# A31T41x register map
Vendor: ABOV Semiconductor Co., Ltd.; File version: 1.0
CPU: CM0PLUS r0p1, little endian, no MPU, no FPU, VTOR, vendor SysTick, 2 interrupt priority bits
Registers are 32-bit, read-write, reset 0x0 unless marked. A register's access mark holds for its fields unless they carry their own. Offsets are from the block's base; [hi:lo] are bit positions; {n}, {i} and the like mark numbered series; 'fields as' and 'values as' point back to an identical list.

## FRT — Free Run Timer
Base 0x40000600
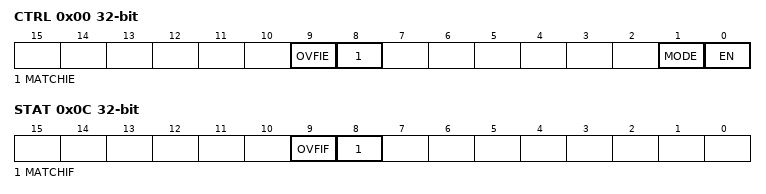
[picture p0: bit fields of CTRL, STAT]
0x00 CTRL — FRT control register
  [9] OVFIE — Whether to enable or disable the FRT counter overflow interrupt in Free-run timer mode (MODE = 0)
    0=Disable (Interrupt Disable); 1=Enable (Interrupt Enable)
  [8] MATCHIE — Whether to enable or disable the FRT counter match interrupt in Periodic timer mode (MODE = 1)
    0=Disable (Interrupt Disable); 1=Enable (Interrupt Enable)
  [1] MODE — FRT mode selection
    0=Free-Run_Timer; 1=Periodic_Timer
  [0] EN — Whether to enable or disable the FRT
    0=Disable (FRT Disable); 1=Enable (FRT Enable)
0x04 MCNT reset 0xFFFFFFFF — FRT match counter register
  [31:0] MCNT — FRTs match counter value
0x08 CNT — FRT counter register
  [31:0] CNT — FRT count data
0x0C STAT — FRT status register
  [9] OVFIF — FRT counter overflow interrupt flag
  [8] MATCHIF — FRT counter match interrupt flag

## I2C — Inter-Integrated Circuit
Base 0x5000A000
Same registers: I2C0 0x4000A000, I2C1 0x4000A100, I2C2 0x4000A200
0x00 DR reset 0xFF — I2C data register
  [7:0] ICDR — In transmit mode, the data stored in this register is outputted from pin SDA in the serial data line. In receive mode, data received at pin SDA is stored in this register; hence, the stored data is loaded by reading this register
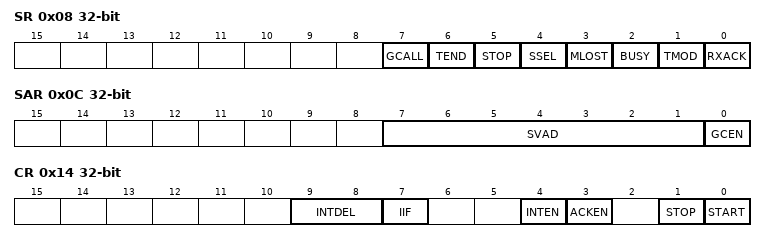
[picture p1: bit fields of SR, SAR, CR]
0x08 SR — I2C status register
  [7] GCALL — This bit signifies different things, depending on whether the I2C is in master or slave mode.
  [6] TEND — One-byte transmit end flag
  [5] STOP — Stop flag
  [4] SSEL — Slave flag
  [3] MLOST — Mastership loss flag
  [2] BUSY ro — Bus busy flag
  [1] TMOD ro — Transmit / receive mode flag
  [0] RXACK — Rx ACK flag
0x0C SAR — I2C slave address register
  [7:1] SVAD — 7-bit slave address
  [0] GCEN — Whether to enable or disable general call
0x14 CR — I2C Control Register
  [9:8] INTDEL — Internal delay between address and data transfers (Or between two data transfers)
    0=1_ICnSCLL (Delay = 1*ICnSCLL); 1=2_ICnSCLL (Delay = 2*ICnSCLL); 2=4_ICnSCLL (Delay = 4*ICnSCLL); 3=8_ICnSCLL (Delay = 8*ICnSCLL)
  [7] IIF ro — Interrupt flag
  [4] INTEN — Whether to enable or disable interrupts
  [3] ACKEN — Whether to enable or disable ACK in receive mode
    0=No ACK signal is generated; 1=ACK (ACK signal is generated)
  [1] STOP — Whether to enable or disable stop
  [0] START — Transmission start in master mode
0x18 SCLL reset 0xFFFF — I2C SCL low duration register
  [15:0] SCLL — SCL low duration value
0x1C SCLH reset 0xFFFF — I2C SCL high duration register
  [15:0] SCLH — SCL high duration value
0x20 SDH reset 0x7FFF — I2C SDA hold register
  [14:0] SDH — SDA hold time value

## CMP — Comparator
Base 0x4000B380
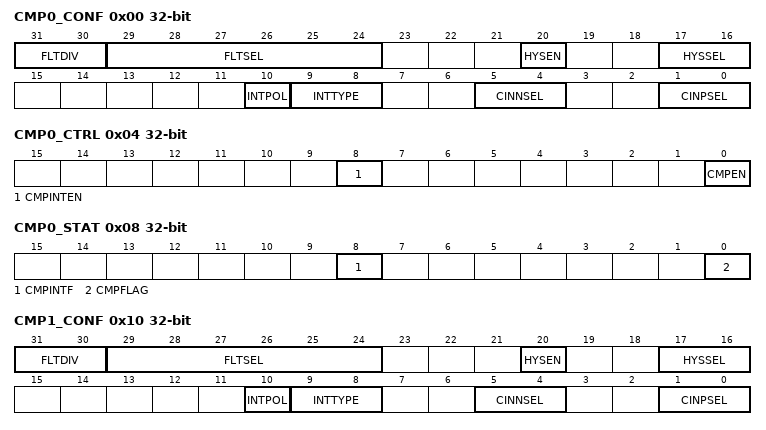
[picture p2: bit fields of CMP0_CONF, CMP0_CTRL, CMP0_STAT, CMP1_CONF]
0x00 CMP0_CONF — Comparator 0 Configure Register
  [31:30] FLTDIV — Digital filter clock divider
  [29:24] FLTSEL — Digital filter count
  [20] HYSEN — Hysteresis enable bit
  [17:16] HYSSEL — Hysteresis selection bit
    0=Hys_40mV (40mV Hysteresis); 1=Hys_80mV (80mV Hysteresis); 2=Hys_120mV (120mV Hysteresis); 3=Hys_160mV (160mV Hysteresis)
  [10] INTPOL — Interrupt polarity selection bit
    0=Low (Low (Falling)); 1=High (Rising)
  [9:8] INTTYPE — Interrupt type selection bit
    0=Disable; 1=Level; 2=Single_edge; 3=Both_edge
  [5:4] CINNSEL — Reference (input -) selection bit
    0=External Reference; 2=Ground; 3=Internal Reference
  [1:0] CINPSEL — Source (input +) selection bit
    0=CP0A; 1=CPB; 2=Ground; 3=Internal Reference
0x04 CMP0_CTRL — Comparator 0 Control Register
  [8] CMPINTEN — Comparator interrupt enable bit
  [0] CMPEN — Comparator enable bit
0x08 CMP0_STAT — Comparator 0 Status Register
  [8] CMPINTF — Comparator interrupt flag bit
    0=Not_occurred (Interrupt not occurred); 1=occurred (Interrupt occurred (writing '1' to the bit clears it to '0'))
  [0] CMPFLAG ro — Comparator output status
    0=Low; 1=High
0x10 CMP1_CONF — Comparator 1 Configure Register
  [31:30] FLTDIV — Digital filter clock divider
  [29:24] FLTSEL — Digital filter count
  [20] HYSEN — Hysteresis enable bit
  [17:16] HYSSEL — Hysteresis selection bit
    values as CMP0_CONF.HYSSEL
  [10] INTPOL — Interrupt polarity selection bit
    0=Low (Low (Falling)); 1=High (Rising)
  [9:8] INTTYPE — Interrupt type selection bit
    0=Disable; 1=Level; 2=Single_edge; 3=Both_edge
  [5:4] CINNSEL — Reference (input -) selection bit
    0=External Reference; 2=Ground; 3=Internal Reference
  [1:0] CINPSEL — Source (input +) selection bit
    0=CP1A; 1=CPB; 2=Ground; 3=Internal Reference
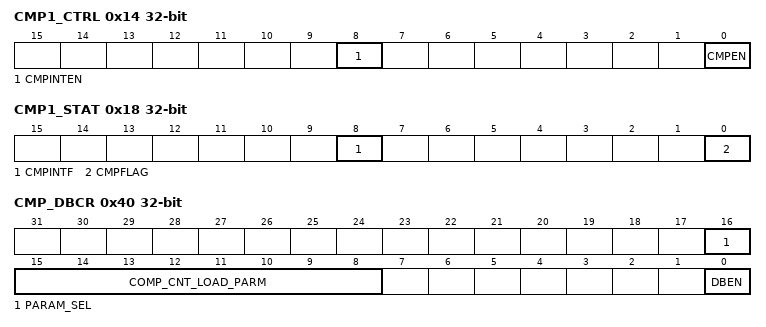
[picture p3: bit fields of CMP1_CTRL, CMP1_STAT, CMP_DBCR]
0x14 CMP1_CTRL — Comparator 1 Control Register
  fields as CMP0_CTRL
0x18 CMP1_STAT — Comparator 1 Status Register
  fields as CMP0_STAT
0x40 CMP_DBCR wo — Comparator Debounce Control Register
  [16] PARAM_SEL — Comparator start-up delay source select
  [15:8] COMP_CNT_LOAD_PARM — Comparator start-up delay count load
  [0] DBEN — Comparator output pin debounce filter enable bit

## CRC — Cyclic Redundancy Check calculation module
Base 0x40082000
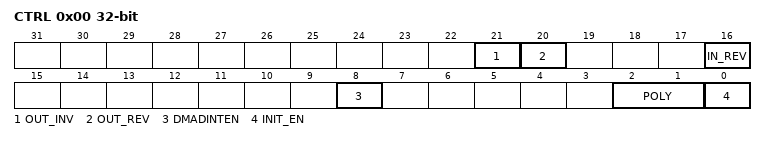
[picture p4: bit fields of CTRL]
0x00 CTRL — CRC control register
  [21] OUT_INV — Whether to enable or disable CRC output data inversion
  [20] OUT_REV — Reverse CRC output data
  [16] IN_REV — Reverse CRC input data
  [8] DMADINTEN — Whether to enable or disable the DMA done interrupt
  [2:1] POLY — Polynomial selection bit
    0=CRC32 (CRC32 (0x04C1_1DB7)); 1=CRC16_USB (CRC16_USB (0x8005)); 2=CRC16_CCITT (CRC16_CCITT (0x1021)); 3=CRC8_CCITT (CRC8_CCITT (0x07))
  [0] INIT_EN wo — Whether or not to apply the CRC initial value register (auto clear)
0x04 INIT reset 0xFFFFFFFF — CRC Init Data Register
  [31:0] INIT_EN — CRC Initial Value
0x08 IDR wo — CRC Input Data Register
  [31:0] IDR — CRC input data bits
0x08 ODR ro reset 0xFFFFFFFF — CRC Output Data Register
  [31:0] ODR — CRC output data bits
0x0C STAT — CRC Status Register
  [8] DMADINT — DMA Done Interrupt Flag Bit

## DBGMCU — Debug MCU Control Register
Base 0x4000F020
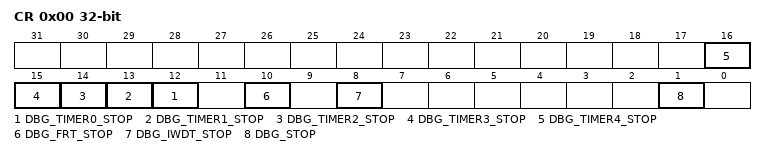
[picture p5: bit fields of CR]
0x00 CR — Debug MCU Register
  [n+12] DBG_TIMER{n}_STOP (n=0..4) — Debug TIMER{n} stopped when core is halted
  [10] DBG_FRT_STOP — Debug FRT stopped when core is halted.
  [8] DBG_IWDT_STOP — Debug independent watchdog stopped when core is halted.
  [1] DBG_STOP — Debug stop mode.
